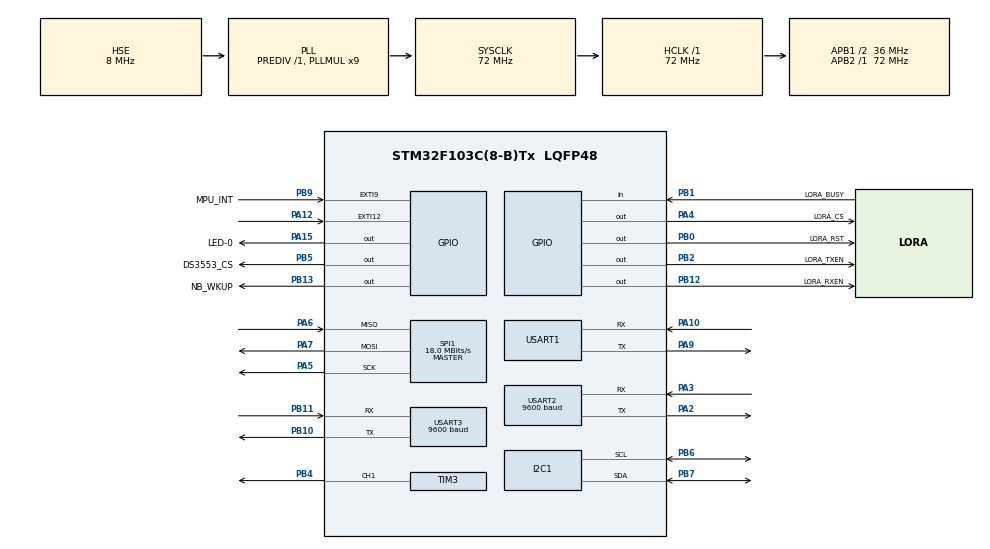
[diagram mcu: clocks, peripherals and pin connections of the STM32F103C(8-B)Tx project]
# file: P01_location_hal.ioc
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I2C1.I2C_Mode=I2C_Standard
Mcu.Family=STM32F1
Mcu.Name=STM32F103C(8-B)Tx
Mcu.Package=LQFP48
NVIC.EXTI9_5_IRQn=true\:0\:0\:false\:false\:true\:true\:true\:true
NVIC.PriorityGroup=NVIC_PRIORITYGROUP_4
NVIC.USART2_IRQn=true\:0\:0\:false\:false\:true\:true\:true\:true
PA10.Mode=Asynchronous
PA10.Signal=USART1_RX
PA12.GPIO_ModeDefaultEXTI=GPIO_MODE_IT_FALLING
PA12.GPIO_PuPd=GPIO_PULLUP
PA12.Signal=GPXTI12
PA13.Mode=Serial_Wire
PA13.Signal=SYS_JTMS-SWDIO
PA14.Mode=Serial_Wire
PA14.Signal=SYS_JTCK-SWCLK
PA15.GPIO_Label=LED-0
PA15.GPIO_Speed=GPIO_SPEED_FREQ_HIGH
PA15.Signal=GPIO_Output
PA2.Mode=Asynchronous
PA2.Signal=USART2_TX
PA3.Mode=Asynchronous
PA3.Signal=USART2_RX
PA4.GPIO_Label=LORA_CS
PA4.GPIO_Speed=GPIO_SPEED_FREQ_HIGH
PA4.PinState=GPIO_PIN_SET
PA4.Signal=GPIO_Output
PA5.Mode=Full_Duplex_Master
PA5.Signal=SPI1_SCK
PA6.Mode=Full_Duplex_Master
PA6.Signal=SPI1_MISO
PA7.Mode=Full_Duplex_Master
PA7.Signal=SPI1_MOSI
PA9.Mode=Asynchronous
PA9.Signal=USART1_TX
PB0.GPIO_Label=LORA_RST
PB0.GPIO_Speed=GPIO_SPEED_FREQ_HIGH
PB0.Signal=GPIO_Output
PB1.GPIO_Label=LORA_BUSY
PB1.Signal=GPIO_Input
PB10.Mode=Asynchronous
PB10.Signal=USART3_TX
PB11.Mode=Asynchronous
PB11.Signal=USART3_RX
PB12.GPIO_Label=LORA_RXEN
PB12.GPIO_Speed=GPIO_SPEED_FREQ_HIGH
PB12.Signal=GPIO_Output
PB13.GPIO_Label=NB_WKUP
PB13.GPIO_Speed=GPIO_SPEED_FREQ_HIGH
PB13.Signal=GPIO_Output
PB2.GPIO_Label=LORA_TXEN
PB2.GPIO_Speed=GPIO_SPEED_FREQ_HIGH
PB2.Signal=GPIO_Output
PB4.Signal=S_TIM3_CH1
PB5.GPIO_Label=DS3553_CS
PB5.GPIO_Speed=GPIO_SPEED_FREQ_HIGH
PB5.PinState=GPIO_PIN_SET
PB5.Signal=GPIO_Output
PB6.Mode=I2C
PB6.Signal=I2C1_SCL
PB7.Mode=I2C
PB7.Signal=I2C1_SDA
PB9.GPIO_Label=MPU_INT
PB9.Signal=GPXTI9
PC14-OSC32_IN.Mode=LSE-External-Oscillator
PC14-OSC32_IN.Signal=RCC_OSC32_IN
PC15-OSC32_OUT.Mode=LSE-External-Oscillator
PC15-OSC32_OUT.Signal=RCC_OSC32_OUT
PD0-OSC_IN.Mode=HSE-External-Oscillator
PD0-OSC_IN.Signal=RCC_OSC_IN
PD1-OSC_OUT.Mode=HSE-External-Oscillator
PD1-OSC_OUT.Signal=RCC_OSC_OUT
ProjectManager.HeapSize=0xA00
ProjectManager.StackSize=0xA00
ProjectManager.TargetToolchain=MDK-ARM V5.32
RCC.AHBFreq_Value=72000000
RCC.APB1CLKDivider=RCC_HCLK_DIV2
RCC.APB1Freq_Value=36000000
RCC.APB1TimFreq_Value=72000000
RCC.APB2Freq_Value=72000000
RCC.APB2TimFreq_Value=72000000
RCC.HCLKFreq_Value=72000000
RCC.PLLMUL=RCC_PLL_MUL9
RCC.PLLSourceVirtual=RCC_PLLSOURCE_HSE
RCC.SYSCLKFreq_VALUE=72000000
RCC.SYSCLKSource=RCC_SYSCLKSOURCE_PLLCLK
RCC.USBFreq_Value=72000000
SH.S_TIM3_CH1.0=TIM3_CH1,PWM Generation1 CH1
SPI1.BaudRatePrescaler=SPI_BAUDRATEPRESCALER_4
SPI1.CalculateBaudRate=18.0 MBits/s
SPI1.Direction=SPI_DIRECTION_2LINES
SPI1.Mode=SPI_MODE_MASTER
SPI1.VirtualType=VM_MASTER
TIM3.Channel-PWM\ Generation1\ CH1=TIM_CHANNEL_1
TIM3.Period=20-1
TIM3.Prescaler=7200-1
TIM3.Pulse-PWM\ Generation1\ CH1=10
USART1.VirtualMode=VM_ASYNC
USART2.BaudRate=9600
USART2.VirtualMode=VM_ASYNC
USART3.BaudRate=9600
USART3.VirtualMode=VM_ASYNC
VP_TIM3_VS_ClockSourceINT.Mode=Internal
board=custom

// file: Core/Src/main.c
/* USER CODE BEGIN Header */
/**
  ******************************************************************************
  * @file           : main.c
  * @brief          : Main program body
  ******************************************************************************
  * @attention
  *
  * Copyright (c) 2026 STMicroelectronics.
  * All rights reserved.
  *
  * This software is licensed under terms that can be found in the LICENSE file
  * in the root directory of this software component.
  * If no LICENSE file comes with this software, it is provided AS-IS.
  *
  ******************************************************************************
  */
/* USER CODE END Header */
#include "main.h"
#include "i2c.h"
#include "spi.h"
#include "tim.h"
#include "usart.h"
#include "gpio.h"

/* USER CODE BEGIN Includes */
#include "Com_debug.h"
#include "App_upload_data.h"
/* USER CODE END Includes */

void SystemClock_Config(void);

int main(void)
{

  /* MCU Configuration--------------------------------------------------------*/

  /* Reset of all peripherals, Initializes the Flash interface and the Systick. */
  HAL_Init();

  /* Configure the system clock */
  SystemClock_Config();

  /* Initialize all configured peripherals */
  MX_GPIO_Init();
  MX_USART1_UART_Init();
  MX_TIM3_Init();
  MX_I2C1_Init();
  MX_USART2_UART_Init();
  MX_USART3_UART_Init();
  MX_SPI1_Init();
  /* USER CODE BEGIN 2 */
  debug_printf("hello world %d",10);
  App_Upload_Data_Init();
  /* USER CODE END 2 */

  /* Infinite loop */
  /* USER CODE BEGIN WHILE */
  while (1)
  {
    // 裸机开发 只能按照代码顺序执行 => 获取GPS信息时无法执行其他的事情
    App_upload_data();
    HAL_Delay(1000);
    /* USER CODE END WHILE */

  }
}

void SystemClock_Config(void)
{
  RCC_OscInitTypeDef RCC_OscInitStruct = {0};
  RCC_ClkInitTypeDef RCC_ClkInitStruct = {0};

  /** Initializes the RCC Oscillators according to the specified parameters
  * in the RCC_OscInitTypeDef structure.
  */
  RCC_OscInitStruct.OscillatorType = RCC_OSCILLATORTYPE_HSE;
  RCC_OscInitStruct.HSEState = RCC_HSE_ON;
  RCC_OscInitStruct.HSEPredivValue = RCC_HSE_PREDIV_DIV1;
  RCC_OscInitStruct.HSIState = RCC_HSI_ON;
  RCC_OscInitStruct.PLL.PLLState = RCC_PLL_ON;
  RCC_OscInitStruct.PLL.PLLSource = RCC_PLLSOURCE_HSE;
  RCC_OscInitStruct.PLL.PLLMUL = RCC_PLL_MUL9;
  if (HAL_RCC_OscConfig(&RCC_OscInitStruct) != HAL_OK)
  {
    Error_Handler();
  }

  /** Initializes the CPU, AHB and APB buses clocks
  */
  RCC_ClkInitStruct.ClockType = RCC_CLOCKTYPE_HCLK|RCC_CLOCKTYPE_SYSCLK
                              |RCC_CLOCKTYPE_PCLK1|RCC_CLOCKTYPE_PCLK2;
  RCC_ClkInitStruct.SYSCLKSource = RCC_SYSCLKSOURCE_PLLCLK;
  RCC_ClkInitStruct.AHBCLKDivider = RCC_SYSCLK_DIV1;
  RCC_ClkInitStruct.APB1CLKDivider = RCC_HCLK_DIV2;
  RCC_ClkInitStruct.APB2CLKDivider = RCC_HCLK_DIV1;

  if (HAL_RCC_ClockConfig(&RCC_ClkInitStruct, FLASH_LATENCY_2) != HAL_OK)
  {
    Error_Handler();
  }
}

void Error_Handler(void)
{
  __disable_irq();
  while (1)
  {
  }
}
